CM_ "IMPORT _bosch_2018.dbc";

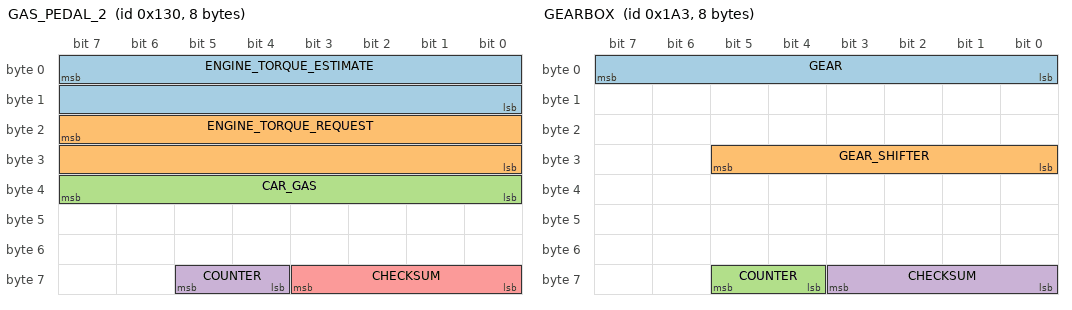
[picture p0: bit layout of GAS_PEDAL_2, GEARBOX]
BO_ 304 GAS_PEDAL_2: 8 PCM
 SG_ ENGINE_TORQUE_ESTIMATE : 7|16@0- (1,0) [-1000|1000] "Nm" EON
 SG_ ENGINE_TORQUE_REQUEST : 23|16@0- (1,0) [-1000|1000] "Nm" EON
 SG_ CAR_GAS : 39|8@0+ (1,0) [0|255] "" EON
 SG_ COUNTER : 61|2@0+ (1,0) [0|3] "" EON
 SG_ CHECKSUM : 59|4@0+ (1,0) [0|15] "" EON

BO_ 419 GEARBOX: 8 PCM
 SG_ GEAR : 7|8@0+ (1,0) [0|255] "" EON
 SG_ GEAR_SHIFTER : 29|6@0+ (1,0) [0|63] "" EON
 SG_ COUNTER : 61|2@0+ (1,0) [0|3] "" EON
 SG_ CHECKSUM : 59|4@0+ (1,0) [0|3] "" EON

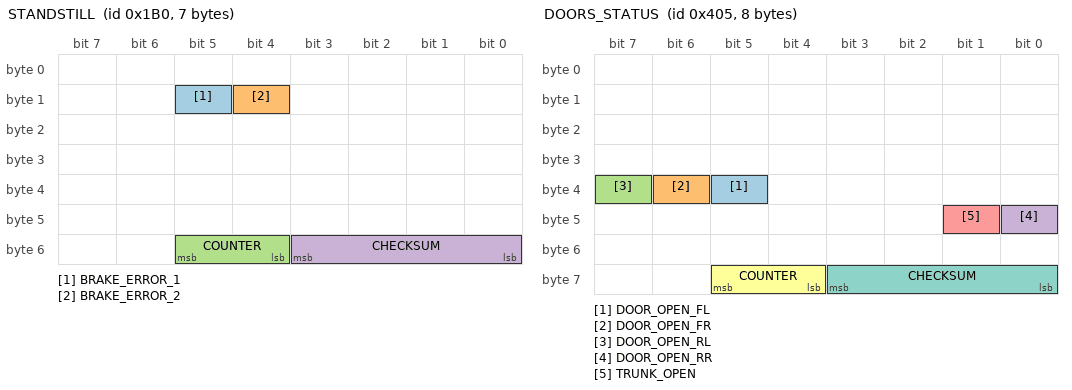
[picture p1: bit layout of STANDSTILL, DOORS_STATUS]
BO_ 432 STANDSTILL: 7 VSA
 SG_ BRAKE_ERROR_1 : 13|1@0+ (1,0) [0|1] "" EON
 SG_ BRAKE_ERROR_2 : 12|1@0+ (1,0) [0|1] "" EON
 SG_ COUNTER : 53|2@0+ (1,0) [0|3] "" EON
 SG_ CHECKSUM : 51|4@0+ (1,0) [0|15] "" EON

BO_ 1029 DOORS_STATUS: 8 BDY
 SG_ DOOR_OPEN_FL : 37|1@0+ (1,0) [0|1] "" EON
 SG_ DOOR_OPEN_FR : 38|1@0+ (1,0) [0|1] "" EON
 SG_ DOOR_OPEN_RL : 39|1@0+ (1,0) [0|1] "" EON
 SG_ DOOR_OPEN_RR : 40|1@0+ (1,0) [0|1] "" EON
 SG_ TRUNK_OPEN : 41|1@0+ (1,0) [0|1] "" EON
 SG_ COUNTER : 61|2@0+ (1,0) [0|3] "" EON
 SG_ CHECKSUM : 59|4@0+ (1,0) [0|15] "" EON

 VAL_ 419 GEAR  10 "R" 1 "D" 0 "P";
 VAL_ 419 GEAR_SHIFTER  32 "D" 16 "N" 8 "R" 4 "P" ;
